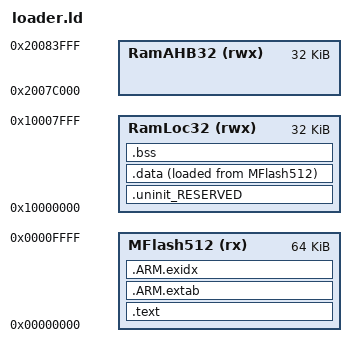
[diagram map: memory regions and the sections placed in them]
MEMORY
{
  MFlash512 (rx) : ORIGIN = 0x0, LENGTH = 64k /* Artificially limiting ROM size of this app */
  RamLoc32 (rwx) : ORIGIN = 0x10000000, LENGTH = 0x8000 /* 32k */
  RamAHB32 (rwx) : ORIGIN = 0x2007c000, LENGTH = 0x8000 /* 32k */

}
  /* Define a symbol for the top of each memory region */
  __top_MFlash512 = 0x0 + 0x80000;
  __top_RamLoc32 = 0x10000000 + 0x8000;
  __top_RamAHB32 = 0x2007c000 + 0x8000;


ENTRY(ResetISR)

SECTIONS
{
	/* Multiple text regions not supported with this license */

	/* MAIN TEXT SECTION */	
	.text : ALIGN(4)
	{
		FILL(0xff)
		KEEP(*(.isr_vector))
		
		/* Global Section Table */
		. = ALIGN(4) ;
		__section_table_start = .;
		__data_section_table = .;
		LONG(LOADADDR(.data));
		LONG(    ADDR(.data)) ;
		LONG(  SIZEOF(.data));
		__data_section_table_end = .;
		__bss_section_table = .;
		LONG(    ADDR(.bss));
		LONG(  SIZEOF(.bss));
		__bss_section_table_end = .;
		__section_table_end = . ;
		/* End of Global Section Table */
		

		*(.after_vectors*)
		
		/* CRP data not supported with this license */
		*(.text*)
		*(.rodata .rodata.*)
		. = ALIGN(4);
		
	} > MFlash512

	/*
	 * for exception handling/unwind - some Newlib functions (in common
	 * with C++ and STDC++) use this.
	 */
	.ARM.extab : ALIGN(4)
	{
		*(.ARM.extab* .gnu.linkonce.armextab.*)
	} > MFlash512
	__exidx_start = .;
	
	.ARM.exidx : ALIGN(4)
	{
		*(.ARM.exidx* .gnu.linkonce.armexidx.*)
	} > MFlash512
	__exidx_end = .;
	
	_etext = .;
		
	/* Multiple data regions not supported with this license */
	
	/* MAIN DATA SECTION */

	.uninit_RESERVED : ALIGN(4)
	{
		KEEP(*(.bss.$RESERVED*))
	} > RamLoc32

	.data : ALIGN(4)
	{
		FILL(0xff)
		_data = .;
		*(vtable)
		*(.data*)
		. = ALIGN(4) ;
		_edata = .;
	} > RamLoc32 AT>MFlash512

	/* Multiple bss regions not supported with this license */

	/* MAIN BSS SECTION */
	.bss : ALIGN(4)
	{
		_bss = .;
		*(.bss*)
		*(COMMON)
		. = ALIGN(4) ;
		_ebss = .;
		PROVIDE(end = .);
	} > RamLoc32
	
	PROVIDE(_pvHeapStart = .);
	PROVIDE(_vStackTop = __top_RamLoc32 - 0);
}
